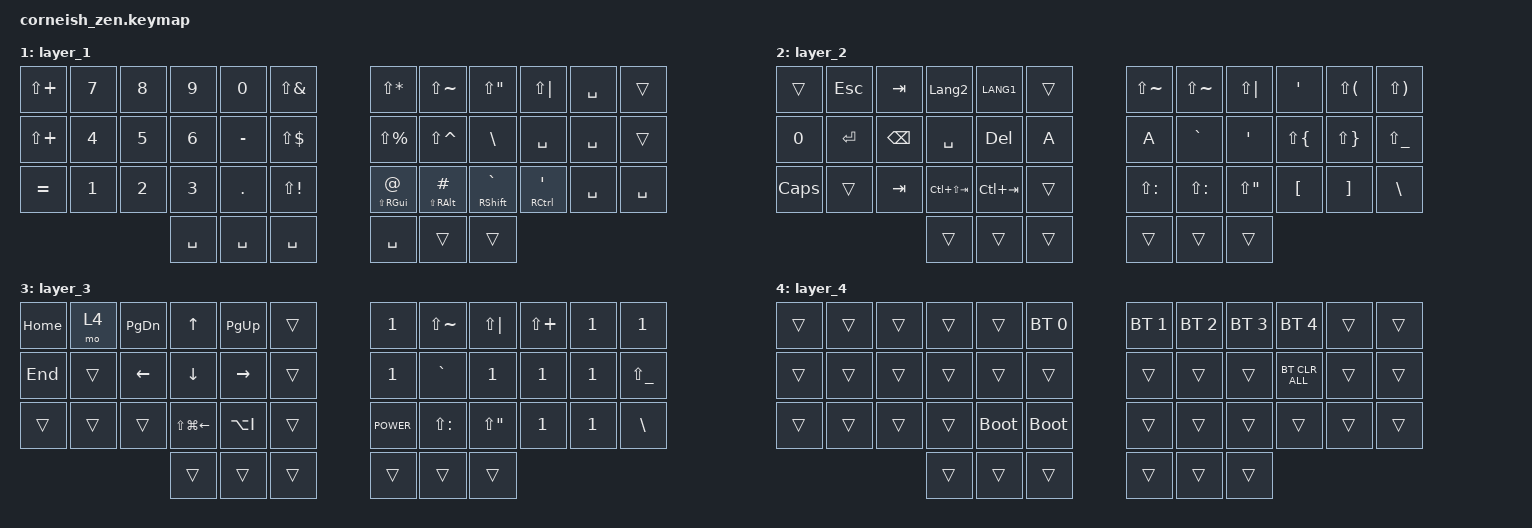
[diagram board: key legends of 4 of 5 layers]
/*
 * Copyright (c) 2020 The ZMK Contributors
 *
 * SPDX-License-Identifier: MIT
 */

#include <behaviors.dtsi>
#include <dt-bindings/zmk/bt.h>
#include <dt-bindings/zmk/keys.h>

/ {
    chosen {
        zmk,matrix_transform = &default_transform;

        // zmk,matrix_transform = &five_column_transform;
    };
};

/ {
    behaviors {
        td0: td0 {
            compatible = "zmk,behavior-tap-dance";
            label = "TD0";
            #binding-cells = <0>;
            bindings = <&kp A>, <&kp B>;
        };

        new_behavior: new_behavior {
            compatible = "zmk,behavior-tap-dance";
            label = "NEW_BEHAVIOR";
            #binding-cells = <0>;
            bindings = <&kp C>, <&kp D>;
        };
    };

    combos {
        compatible = "zmk,combos";

        f1 {
            bindings = <&kp F1>;
            key-positions = <0 12>;
        };

        f2 {
            bindings = <&kp F2>;
            key-positions = <1 13>;
        };

        f3 {
            bindings = <&kp F3>;
            key-positions = <2 14>;
        };

        f4 {
            bindings = <&kp F4>;
            key-positions = <3 15>;
        };

        f5 {
            bindings = <&kp F5>;
            key-positions = <4 16>;
        };

        f6 {
            bindings = <&kp F6>;
            key-positions = <5 17>;
        };

        f7 {
            bindings = <&kp F7>;
            key-positions = <6 18>;
        };

        f8 {
            bindings = <&kp F8>;
            key-positions = <7 19>;
        };

        f9 {
            bindings = <&kp F9>;
            key-positions = <8 20>;
        };

        f10 {
            bindings = <&kp F10>;
            key-positions = <21 9>;
        };

        f11 {
            bindings = <&kp F11>;
            key-positions = <12 24>;
        };

        esc {
            bindings = <&kp ESC>;
            key-positions = <0 1>;
        };

        tab {
            bindings = <&kp ENTER>;
            key-positions = <12 13>;
        };

        moodoru {
            bindings = <&kp LA(LEFT)>;
            key-positions = <25 13>;
        };

        susumu {
            bindings = <&kp LA(RIGHT)>;
            key-positions = <14 26>;
        };

        stop {
            bindings = <&kp C_PLAY_PAUSE>;
            key-positions = <16 28>;
        };

        mainasu {
            bindings = <&kp MINUS>;
            key-positions = <10 11>;
        };

        tabyoko {
            bindings = <&kp LC(LS(TAB))>;
            key-positions = <1 2>;
        };

        tabR {
            bindings = <&kp LC(TAB)>;
            key-positions = <3 4>;
        };
    };

    macros {
        macro1: macro1 {
            compatible = "zmk,behavior-macro";
            #binding-cells = <0>;
            bindings =
                <&kp LC(LS(LEFT_BRACKET))>,
                <&macro_wait_time 200>,
                <&kp LC(V)>;

            label = "MACRO1";
        };
    };

    keymap {
        compatible = "zmk,keymap";

        default_layer {
            display-name = "QWERTY";

            // --------------------------------------------------------------------------------
            // |  TAB |  Q  |  W  |  E  |  R  |  T  |   |  Y  |  U   |  I  |  O  |  P  | BKSP |
            // | CTRL |  A  |  S  |  D  |  F  |  G  |   |  H  |  J   |  K  |  L  |  ;  |  '   | 
            // | SHFT |  Z  |  X  |  C  |  V  |  B  |   |  N  |  M   |  ,  |  .  |  /  | ESC  |

            bindings = <
&lt 1 Q      &kp W        &kp E           &kp R           &kp T    &kp Y    &kp U  &kp I               &kp O              &lt 4 P          &kp A  &kp S
&lt 2 A      &lt 3 S      &kp D           &mt SPACE F     &kp G    &kp H    &kp J  &kp K               &lt 2 L            &lt 1 SEMICOLON  &kp Z  &kp X
&mt LCTRL Z  &mt LSHFT X  &mt LEFT_ALT C  &mt LEFT_GUI V  &lt 3 B  &kp N    &kp M  &mt LEFT_ALT COMMA  &mt RSHIFT PERIOD  &mt RCTRL SLASH  &kp R  &kp R
            >;
        };

        layer_1 {
            bindings = <
&kp LS(PLUS)  &kp N7  &kp N8  &kp N9     &kp N0     &kp LS(AMPS)    &kp LS(STAR)          &kp LS(TILDE)      &kp LS(DQT)       &kp LS(PIPE)   &kp SPACE  &trans
&kp LS(PLUS)  &kp N4  &kp N5  &kp N6     &kp MINUS  &kp LS(DLLR)    &kp LS(PRCNT)         &kp LS(CARET)      &kp BSLH          &kp SPACE      &kp SPACE  &trans
&kp EQUAL     &kp N1  &kp N2  &kp N3     &kp DOT    &kp LS(EXCL)    &mt LS(RGUI) AT_SIGN  &mt LS(RALT) HASH  &mt RSHIFT GRAVE  &mt RCTRL SQT  &kp SPACE  &kp SPACE
                              &kp SPACE  &kp SPACE  &kp SPACE       &kp SPACE             &trans             &trans
            >;
        };

        layer_2 {
            bindings = <
&trans    &kp ESC  &kp TAB   &kp LANGUAGE_2   &kp LANG1    &trans    &kp LS(TILDE)  &kp LS(TILDE)  &kp LS(PIPE)  &kp SQT       &kp LS(LPAR)  &kp LS(RPAR)
&kp N0    &kp RET  &kp BSPC  &kp SPACE        &kp DELETE   &kp A     &kp A          &kp GRAVE      &kp SQT       &kp LS(LBRC)  &kp LS(RBRC)  &kp LS(UNDER)
&kp CLCK  &trans   &kp TAB   &kp LC(LS(TAB))  &kp LC(TAB)  &trans    &kp LS(COLON)  &kp LS(COLON)  &kp LS(DQT)   &kp LBKT      &kp RBKT      &kp BSLH
                             &trans           &trans       &trans    &trans         &trans         &trans
            >;
        };

        layer_3 {
            bindings = <
&kp HOME  &mo 4   &kp PAGE_DOWN  &kp UP            &kp PAGE_UP  &trans    &kp N1       &kp LS(TILDE)  &kp LS(PIPE)  &kp LS(PLUS)  &kp N1  &kp N1
&kp END   &trans  &kp LEFT       &kp DOWN          &kp RIGHT    &trans    &kp N1       &kp GRAVE      &kp N1        &kp N1        &kp N1  &kp LS(UNDER)
&trans    &trans  &trans         &kp LS(LG(LEFT))  &kp LA(I)    &trans    &kp C_POWER  &kp LS(COLON)  &kp LS(DQT)   &kp N1        &kp N1  &kp BSLH
                                 &trans            &trans       &trans    &trans       &trans         &trans
            >;
        };

        layer_4 {
            bindings = <
&trans  &trans  &trans  &trans  &trans       &bt BT_SEL 0    &bt BT_SEL 1  &bt BT_SEL 2  &bt BT_SEL 3  &bt BT_SEL 4    &trans  &trans
&trans  &trans  &trans  &trans  &trans       &trans          &trans        &trans        &trans        &bt BT_CLR_ALL  &trans  &trans
&trans  &trans  &trans  &trans  &bootloader  &bootloader     &trans        &trans        &trans        &trans          &trans  &trans
                        &trans  &trans       &trans          &trans        &trans        &trans
            >;
        };
    };
};
